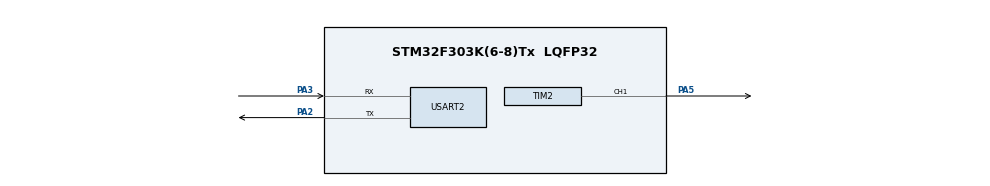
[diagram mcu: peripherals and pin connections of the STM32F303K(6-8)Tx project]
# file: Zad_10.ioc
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Dma.Request0=USART2_RX
Dma.Request1=USART2_TX
Dma.USART2_RX.0.Direction=DMA_PERIPH_TO_MEMORY
Dma.USART2_RX.0.Instance=DMA1_Channel6
Dma.USART2_RX.0.MemDataAlignment=DMA_MDATAALIGN_BYTE
Dma.USART2_RX.0.MemInc=DMA_MINC_ENABLE
Dma.USART2_RX.0.Mode=DMA_NORMAL
Dma.USART2_RX.0.PeriphDataAlignment=DMA_PDATAALIGN_BYTE
Dma.USART2_RX.0.PeriphInc=DMA_PINC_DISABLE
Dma.USART2_RX.0.Priority=DMA_PRIORITY_MEDIUM
Dma.USART2_TX.1.Direction=DMA_MEMORY_TO_PERIPH
Dma.USART2_TX.1.Instance=DMA1_Channel7
Dma.USART2_TX.1.MemDataAlignment=DMA_MDATAALIGN_BYTE
Dma.USART2_TX.1.MemInc=DMA_MINC_ENABLE
Dma.USART2_TX.1.Mode=DMA_NORMAL
Dma.USART2_TX.1.PeriphDataAlignment=DMA_PDATAALIGN_BYTE
Dma.USART2_TX.1.PeriphInc=DMA_PINC_DISABLE
Dma.USART2_TX.1.Priority=DMA_PRIORITY_MEDIUM
Mcu.Family=STM32F3
Mcu.Name=STM32F303K(6-8)Tx
Mcu.Package=LQFP32
NVIC.DMA1_Channel6_IRQn=true\:0\:0\:false\:false\:true\:false\:true
NVIC.DMA1_Channel7_IRQn=true\:0\:0\:false\:false\:true\:false\:true
NVIC.PriorityGroup=NVIC_PRIORITYGROUP_4
NVIC.TIM3_IRQn=true\:0\:0\:false\:false\:true\:true\:true
NVIC.USART2_IRQn=true\:0\:0\:false\:false\:true\:true\:true
PA2.Mode=Asynchronous
PA2.Signal=USART2_TX
PA3.Mode=Asynchronous
PA3.Signal=USART2_RX
PA5.Signal=S_TIM2_CH1_ETR
ProjectManager.HeapSize=0x200
ProjectManager.StackSize=0x400
ProjectManager.TargetToolchain=STM32CubeIDE
RCC.AHBFreq_Value=8000000
RCC.APB1Freq_Value=8000000
RCC.APB2Freq_Value=8000000
RCC.CortexFreq_Value=8000000
RCC.HSE_VALUE=8000000
RCC.HSI_VALUE=8000000
RCC.SYSCLKFreq_VALUE=8000000
SH.S_TIM2_CH1_ETR.0=TIM2_CH1,PWM Generation1 CH1
TIM2.Channel-PWM\ Generation1\ CH1=TIM_CHANNEL_1
TIM2.Period=99
TIM2.Prescaler=799
TIM3.Channel-Output\ Compare1\ No\ Output=TIM_CHANNEL_1
TIM3.OCMode_1=TIM_OCMODE_ACTIVE
TIM3.Period=999
TIM3.Prescaler=7999
USART2.VirtualMode-Asynchronous=VM_ASYNC
VP_TIM2_VS_ClockSourceINT.Mode=Internal
VP_TIM3_VS_ClockSourceINT.Mode=Internal
VP_TIM3_VS_no_output1.Mode=Output Compare1 No Output
board=custom

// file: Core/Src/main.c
/* USER CODE BEGIN Header */
/**
  ******************************************************************************
  * @file           : main.c
  * @brief          : Main program body
  ******************************************************************************
  * @attention
  *
  * <h2><center>&copy; Copyright (c) 2021 STMicroelectronics.
  * All rights reserved.</center></h2>
  *
  * This software component is licensed by ST under BSD 3-Clause license,
  * the "License"; You may not use this file except in compliance with the
  * License. You may obtain a copy of the License at:
  *                        opensource.org/licenses/BSD-3-Clause
  *
  ******************************************************************************
  */
/* USER CODE END Header */
#include "main.h"
#include "dma.h"
#include "tim.h"
#include "usart.h"
#include "gpio.h"

/* USER CODE BEGIN PV */
// Space for your global variables

//uint8_t tx_data[] = "I"; 			// odosielane data
uint8_t rx_data[20];	 			// prijimane data
uint8_t start = 0;					// zaciatok citania retazca
uint8_t pwm_array[2] = {'0','0'};	// pomocne pole
uint8_t pwm_int = 0;				// hodnota PWM
uint8_t mode = 0; 				// 0 pre manual, 1 pre auto, 2 pre pwm

/* USER CODE END PV */

void SystemClock_Config(void);

/* USER CODE BEGIN 0 */
// Function processing DMA Rx data
void receive_dma_data(const uint8_t* data, uint16_t len);
/* USER CODE END 0 */

int main(void)
{

  /* MCU Configuration--------------------------------------------------------*/

  /* Reset of all peripherals, Initializes the Flash interface and the Systick. */

  LL_APB2_GRP1_EnableClock(LL_APB2_GRP1_PERIPH_SYSCFG);
  LL_APB1_GRP1_EnableClock(LL_APB1_GRP1_PERIPH_PWR);

  NVIC_SetPriorityGrouping(NVIC_PRIORITYGROUP_4);

  /* System interrupt init*/
  /* SysTick_IRQn interrupt configuration */
  //NVIC_SetPriority(SysTick_IRQn, NVIC_EncodePriority(NVIC_GetPriorityGrouping(),15, 0));

  /* Configure the system clock */
  SystemClock_Config();

  /* Initialize all configured peripherals */
  MX_GPIO_Init();
  MX_DMA_Init();
  MX_TIM2_Init();
  MX_TIM3_Init();
  MX_USART2_UART_Init();
  /* USER CODE BEGIN 2 */
  USART2_RegisterCallback(receive_dma_data);
  LL_TIM_CC_EnableChannel(TIM2, LL_TIM_CHANNEL_CH1);
  LL_TIM_EnableIT_UPDATE(TIM2);
  LL_TIM_EnableCounter(TIM2);
  LL_TIM_EnableIT_UPDATE(TIM3);
  LL_TIM_EnableCounter(TIM3);
  /* USER CODE END 2 */

  /* Infinite loop */
  while (1)
  {

    /* USER CODE BEGIN 3 */
	#if POLLING
			//Polling for new data, no interrupts
			USART2_CheckDmaReception();
			LL_mDelay(10);
	#else
		USART2_PutBuffer(tx_data, sizeof(tx_data));
		LL_mDelay(1000);
	#endif

	//USART2_PutBuffer(tx_data, sizeof(tx_data));
	LL_mDelay(100);
  }
  /* USER CODE END 3 */
}

void SystemClock_Config(void)
{
  LL_FLASH_SetLatency(LL_FLASH_LATENCY_0);
  /* USER CODE BEGIN 4 */
  if(LL_FLASH_GetLatency() != LL_FLASH_LATENCY_0)
    {
    Error_Handler();
    }
    LL_RCC_HSI_Enable();
  /* USER CODE END 4 */
  while(LL_FLASH_GetLatency()!= LL_FLASH_LATENCY_0)
  {
  }
  LL_RCC_HSI_Enable();

   /* Wait till HSI is ready */
  while(LL_RCC_HSI_IsReady() != 1)
  {

  }
  LL_RCC_HSI_SetCalibTrimming(16);
  LL_RCC_SetAHBPrescaler(LL_RCC_SYSCLK_DIV_1);
  LL_RCC_SetAPB1Prescaler(LL_RCC_APB1_DIV_1);
  LL_RCC_SetAPB2Prescaler(LL_RCC_APB2_DIV_1);
  LL_RCC_SetSysClkSource(LL_RCC_SYS_CLKSOURCE_HSI);

   /* Wait till System clock is ready */
  while(LL_RCC_GetSysClkSource() != LL_RCC_SYS_CLKSOURCE_STATUS_HSI)
  {

  }
  LL_Init1msTick(8000000);
  /* USER CODE BEGIN 5 */
  LL_SYSTICK_SetClkSource(LL_SYSTICK_CLKSOURCE_HCLK);
  /* USER CODE END 5 */
  LL_SetSystemCoreClock(8000000);
}

/* USER CODE BEGIN 7 */
void receive_dma_data(const uint8_t* data, uint16_t len)
{
	if (start == 0) //znaci ze sme este nenacali citanie znakom $
	{
		for(uint8_t i = 0; i<len; i++)
		{
			if(*(data+i)=='$' && start == 0) //prijali sme $
			{
				start = 1;
			}

			if(start == 1 && *(data+i)!='$') //prijali sme znak $ a zaciname citat ale $ nezapisujeme
			{
				rx_data[i-1] = *(data+i);
			}

			if(i>0 && start == 1 && *(data+i)=='$')
			{
				start = 0;

				// Rozlisujeme aky retazec sme prijali
				if(strcmp(rx_data, "manual") == 0)
				{
					mode = 0;
					memset(rx_data,'\0',10); //zmazeme retazec z arrayu
				}
				if(strcmp(rx_data, "auto") == 0)
				{
					mode = 1;
					memset(rx_data,'\0',10); //zmazeme retazec z arrayu
				}

				if(mode == 0 && rx_data[0]=='P' && rx_data[1]=='W' && rx_data[2]=='M' &&  (rx_data[3]>= '0' && rx_data[3]<= '9') && (rx_data[4]>= '0' && rx_data[4]<= '9')) //mozeme sa prepnut len ak sme v manual mode
				{
					pwm_array[0] = rx_data[3];
					pwm_array[1] = rx_data[4];

					pwm_int = atoi(pwm_array); //transformujeme hodnoty arrayu pwm_array na integer pwm pre dalsie pouzitie

					memset(rx_data,'\0',10); //zmazeme retazec z arrayu

					mode = 0;
				}

			}
		}
		for(uint8_t i = 0; i<len; i++)
		{
			rx_data[i] = 0;
		}
	}
}

void setDutyCycle(uint8_t duty)
{
	uint8_t duty_value = duty;
	TIM2->CCR1 = duty_value;
}
/* USER CODE END 7 */

void Error_Handler(void)
{
  __disable_irq();
  while (1)
  {
  }
}

/************************ (C) COPYRIGHT STMicroelectronics *****END OF FILE****/
